# ATtiny417 register map
Vendor: Atmel; File version: 1.0
CPU: other r0p0, little endian, no MPU, no FPU, 4 interrupt priority bits
Registers are 8-bit, read-write, reset 0x0 unless marked. A register's access mark holds for its fields unless they carry their own. Offsets are from the block's base; lines under a group give offsets from that group; [hi:lo] are bit positions; {n}, {i} and the like mark numbered series; 'fields as' and 'values as' point back to an identical list; <NAME> marks a mode.

## Memory map
0x00800000 VPORTA size 0x4 — Virtual Ports
0x00800004 VPORTB size 0x4 — Virtual Ports
0x00800008 VPORTC size 0x4 — Virtual Ports
0x0080001C GPIO size 0x4 — General Purpose IO
0x00800034 CPU blocks up to offset 0xB
0x00800040 RSTCTRL size 0x2 — Reset controller
0x00800050 SLPCTRL size 0x1 — Sleep Controller
0x00800060 CLKCTRL blocks up to offset 0x1D — Clock controller
0x00800080 BOD blocks up to offset 0xC — Bod interface
0x008000A0 VREF size 0x2 — Voltage reference
0x00800100 WDT size 0x2 — Watch-Dog Timer
0x00800110 CPUINT size 0x4 — Interrupt Controller
0x00800120 CRCSCAN size 0x3
0x00800140 RTC blocks up to offset 0x16 — Real-Time Counter
0x00800180 EVSYS blocks up to offset 0x24 — Event System
0x008001C0 CCL blocks up to offset 0xD — Configurable Custom Logic
0x00800200 PORTMUX size 0x4 — Port Multiplexer
0x00800400 PORTA blocks up to offset 0x18 — I/O Ports
0x00800420 PORTB blocks up to offset 0x18 — I/O Ports
0x00800440 PORTC blocks up to offset 0x18 — I/O Ports
0x00800600 ADC0 blocks up to offset 0x17 — Analog to Digital Converter
0x00800670 AC0 blocks up to offset 0x8 — Analog Comparator
0x00800680 DAC0 size 0x2 — Digital to Analog Converter
0x00800800 USART0 blocks up to offset 0xF — Universal Synchronous and Asynchronous Receiver and Transmitter
0x00800810 TWI0 blocks up to offset 0xF — Two-Wire Interface
0x00800820 SPI0 size 0x5 — Serial Peripheral Interface
0x00800A00 TCA0 blocks up to offset 0x3E — 16-bit Timer/Counter Type A
0x00800A40 TCB0 blocks up to offset 0xE — 16-bit Timer Type B
0x00800A80 TCD0 blocks up to offset 0x30 — Timer Counter D
0x00800F01 SYSCFG size 0x2 — System Configuration Registers
0x00801000 NVMCTRL blocks up to offset 0xA — Non-volatile Memory Controller
0x00801100 SIGROW blocks up to offset 0x26 — Signature row
0x00801280 FUSE blocks up to offset 0x9 — Fuses
0x0080128A LOCKBIT size 0x1
0x00801300 USERROW size 0x20

## Interrupts
1 CRCSCAN_NMI (CPU)
2 BOD_VLM (CPU)
3 PORTA_PORT (CPU)
4 PORTB_PORT (CPU)
5 PORTC_PORT (CPU)
6 RTC_CNT (CPU)
7 RTC_PIT (CPU)
8 TCA0_LUNF_OVF (CPU)
9 TCA0_HUNF (CPU)
10 TCA0_CMP0_LCMP0 (CPU)
11 TCA0_CMP1_LCMP1 (CPU)
12 TCA0_CMP2_LCMP2 (CPU)
13 TCB0_INT (CPU)
14 TCD0_OVF (CPU)
15 TCD0_TRIG (CPU)
16 AC0_AC (CPU)
17 ADC0_RESRDY (CPU)
18 ADC0_WCOMP (CPU)
19 TWI0_TWIS (CPU)
20 TWI0_TWIM (CPU)
21 SPI0_INT (CPU)
22 USART0_RXC (CPU)
23 USART0_DRE (CPU)
24 USART0_TXC (CPU)
25 NVMCTRL_EE (CPU)

## AC0 — Analog Comparator
Base 0x00800670
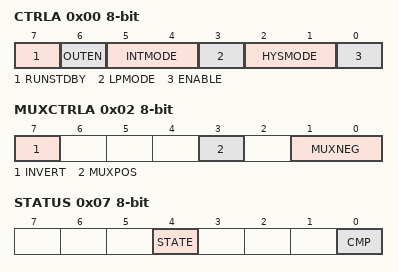
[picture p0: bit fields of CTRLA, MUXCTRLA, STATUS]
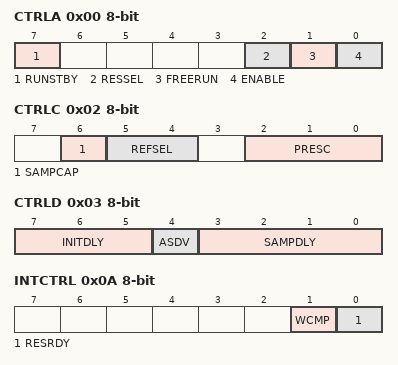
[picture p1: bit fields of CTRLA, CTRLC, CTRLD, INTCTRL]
0x00 CTRLA — Control A
  [7] RUNSTDBY — Run in Standby Mode
  [6] OUTEN — Output Buffer Enable
  [5:4] INTMODE — Interrupt Mode
    0=BOTHEDGE (Any Edge); 2=NEGEDGE (Negative Edge); 3=POSEDGE (Positive Edge)
  [3] LPMODE — Low Power Mode
    0=DIS (Low power mode disabled); 1=EN (Low power mode enabled)
  [2:1] HYSMODE — Hysteresis Mode
    0=OFF (No hysteresis); 1=10mV hysteresis; 2=25mV hysteresis; 3=50mV hysteresis
  [0] ENABLE
0x02 MUXCTRLA — Mux Control A
  [7] INVERT — Invert AC Output
  [3] MUXPOS — Positive Input MUX Selection
    0=PIN0 (Positive Pin 0); 1=PIN1 (Positive Pin 1)
  [1:0] MUXNEG — Negative Input MUX Selection
    0=PIN0 (Negative Pin 0); 1=PIN1 (Negative Pin 1); 2=VREF (Voltage Reference); 3=DAC (DAC output)
0x06 INTCTRL — Interrupt Control
  [0] CMP — Analog Comparator 0 Interrupt Enable
0x07 STATUS
  [4] STATE ro — Analog Comparator State
  [0] CMP — Analog Comparator Interrupt Flag

## ADC0 — Analog to Digital Converter
Base 0x00800600
0x00 CTRLA — Control A
  [7] RUNSTBY — Run standby mode
  [2] RESSEL — ADC Resolution
    0=10BIT (10-bit mode); 1=8BIT (8-bit mode)
  [1] FREERUN — ADC Freerun mode
  [0] ENABLE — ADC Enable
0x01 CTRLB — Control B
  [2:0] SAMPNUM — Accumulation Samples
    0=ACC1 (1 ADC sample); 1=ACC2 (Accumulate 2 samples); 2=ACC4 (Accumulate 4 samples); 3=ACC8 (Accumulate 8 samples); 4=ACC16 (Accumulate 16 samples); 5=ACC32 (Accumulate 32 samples); 6=ACC64 (Accumulate 64 samples)
0x02 CTRLC — Control C
  [6] SAMPCAP — Sample Capacitance Selection
  [5:4] REFSEL — Reference Selection
    0=INTREF (Internal reference); 1=VDDREF
  [2:0] PRESC — Clock Pre-scaler
    0=DIV2 (CLK_PER divided by 2); 1=DIV4 (CLK_PER divided by 4); 2=DIV8 (CLK_PER divided by 8); 3=DIV16 (CLK_PER divided by 16); 4=DIV32 (CLK_PER divided by 32); 5=DIV64 (CLK_PER divided by 64); 6=DIV128 (CLK_PER divided by 128); 7=DIV256 (CLK_PER divided by 256)
0x03 CTRLD — Control D
  [7:5] INITDLY — Initial Delay Selection
    0=DLY0 (Delay 0 CLK_ADC cycles); 1=DLY16 (Delay 16 CLK_ADC cycles); 2=DLY32 (Delay 32 CLK_ADC cycles); 3=DLY64 (Delay 64 CLK_ADC cycles); 4=DLY128 (Delay 128 CLK_ADC cycles); 5=DLY256 (Delay 256 CLK_ADC cycles)
  [4] ASDV — Automatic Sampling Delay Variation
    0=ASVOFF (The Automatic Sampling Delay Variation is disabled); 1=ASVON (The Automatic Sampling Delay Variation is enabled)
  [3:0] SAMPDLY — Sampling Delay Selection
0x04 CTRLE — Control E
  [2:0] WINCM — Window Comparator Mode
    0=NONE (No Window Comparison); 1=BELOW (Below Window); 2=ABOVE (Above Window); 3=INSIDE (Inside Window); 4=OUTSIDE (Outside Window)
0x05 SAMPCTRL — Sample Control
  [4:0] SAMPLEN — Sample lenght
0x06 MUXPOS — Positive mux input
  [4:0] MUXPOS — Analog Channel Selection Bits
    {v}=AIN{v} (ADC input pin {v}) (v=0..11); 28=DAC0; 29=INTREF (Internal Ref); 30=TEMPSENSE (Temp sensor); 31=GND
0x08 COMMAND
  [0] STCONV — Start Conversion Operation
0x09 EVCTRL — Event Control
  [0] STARTEI — Start Event Input Enable
0x0A INTCTRL — Interrupt Control
  [1] WCMP — Window Comparator Interrupt Enable
  [0] RESRDY — Result Ready Interrupt Enable
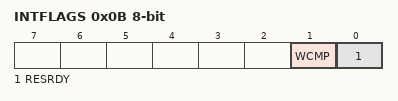
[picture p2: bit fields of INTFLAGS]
0x0B INTFLAGS — Interrupt Flags
  [1] WCMP — Window Comparator Flag
  [0] RESRDY — Result Ready Flag
0x0C DBGCTRL — Debug Control
  [0] DBGRUN — Debug run
0x0D TEMP — Temporary Data
  [7:0] TEMP — Temporary
0x10 RES 16-bit ro (reset mask 0xFF) — ADC Accumulator Result
0x12 WINLT 16-bit (reset mask 0xFF) — Window comparator low threshold
0x14 WINHT 16-bit (reset mask 0xFF) — Window comparator high threshold
0x16 CALIB — Calibration
  [0] DUTYCYC — Duty Cycle
    0=DUTY50 (50% Duty cycle); 1=DUTY25 (25% Duty cycle)
